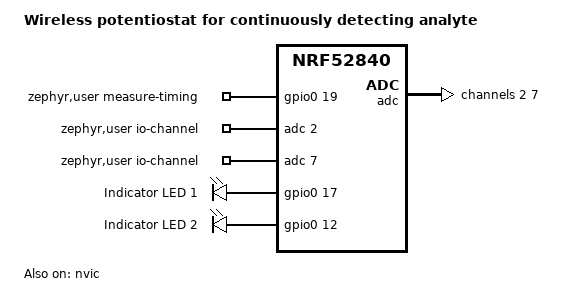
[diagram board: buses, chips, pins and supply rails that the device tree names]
/dts-v1/;
#include <nordic/nrf52840_qfaa.dtsi>
#include "ContinuousBiosensing-pinctrl.dtsi"

/ {
	model = "Wireless potentiostat for continuously detecting analyte ";
	compatible = "VRG,ContinuousBiosensing";

	chosen {
		zephyr,sram = &sram0;
		zephyr,flash = &flash0;
		zephyr,code-partition = &slot0_partition;
	};

	 zephyr,user {
        io-channels = <&adc 2>, <&adc 7>;
		measure-timing-gpios = <&gpio0 19 0>;  // Use P0.19
    };

	leds {
		compatible = "gpio-leds";
		leds_0: led_0 {
			label = "Indicator LED 1";
			gpios = <&gpio0 17 0>;
		};
		leds_1: led_1 {
			label = "Indicator LED 2";
			gpios = <&gpio0 12 0>;
		};
	};

	aliases {
		led0 = &leds_0;
		led1 = &leds_1;
	};
};

&flash0 {
	partitions {
		compatible = "fixed-partitions";
		#address-cells = <1>;
		#size-cells = <1>;

		boot_partition: partition@0 {
			label = "mcuboot";
			reg = <0x00000000 DT_SIZE_K(48)>;
		};

		slot0_partition: partition@c000 {
			label = "image-0";
			reg = <0x0000c000 DT_SIZE_K(472)>;
		};

		slot1_partition: partition@82000 {
			label = "image-1";
			reg = <0x00082000 DT_SIZE_K(472)>;
		};

		storage_partition: partition@f8000 {
			label = "storage";
			reg = <0x000f8000 DT_SIZE_K(32)>;
		};
	};
};
&gpio0 {
	status = "okay";
};

&gpiote {
	status = "okay";
};

&adc {
	status = "okay";
	#address-cells = <1>;
	#size-cells = <0>;
	
	channel@2 {
		reg = <2>;
		zephyr,gain = "ADC_GAIN_1_6";
		zephyr,reference = "ADC_REF_INTERNAL";
		zephyr,acquisition-time = <ADC_ACQ_TIME_DEFAULT>;
		zephyr,input-positive = <NRF_SAADC_AIN2>; /* P0.04 */
		zephyr,resolution = <12>;
	};
	channel@7 {
		reg = <7>;
		zephyr,gain = "ADC_GAIN_1_6";
		zephyr,reference = "ADC_REF_INTERNAL";
		zephyr,acquisition-time = <ADC_ACQ_TIME_DEFAULT>;
		zephyr,input-positive = <NRF_SAADC_AIN7>; /* P0.31 */
		zephyr,resolution = <12>;
	};
	
};


&nvic {
	status = "okay";
};

&gpio1 {
	status = "okay";
};
